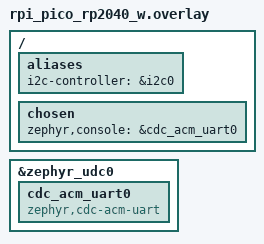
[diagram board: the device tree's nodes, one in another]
/ {
	aliases {
		i2c-controller = &i2c0;
	};
};

// USB Console
/ {
	chosen {
		zephyr,console = &cdc_acm_uart0;
	};
};

&zephyr_udc0 {
	cdc_acm_uart0: cdc_acm_uart0 {
		compatible = "zephyr,cdc-acm-uart";
	};
};
